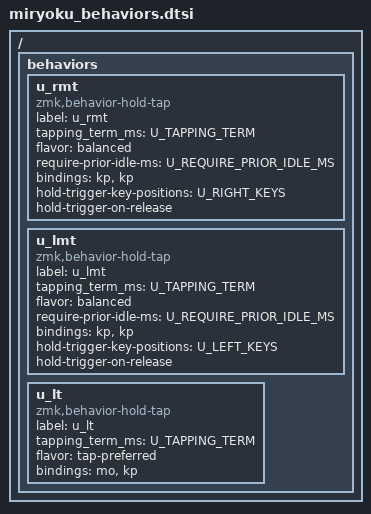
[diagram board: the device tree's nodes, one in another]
// Copyright 2022 Manna Harbour
// https://github.com/manna-harbour/miryoku

/ {
  behaviors {
    u_rmt: u_rmt {
      compatible = "zmk,behavior-hold-tap";
      label = "u_rmt";
      #binding-cells = <2>;
      tapping_term_ms = <U_TAPPING_TERM>;
      flavor = "balanced";
      require-prior-idle-ms = <U_REQUIRE_PRIOR_IDLE_MS>;
      bindings = <&kp>, <&kp>;
      hold-trigger-key-positions = <U_RIGHT_KEYS>;
      hold-trigger-on-release; 
    };

    u_lmt: u_lmt {
      compatible = "zmk,behavior-hold-tap";
      label = "u_lmt";
      #binding-cells = <2>;
      tapping_term_ms = <U_TAPPING_TERM>;
      flavor = "balanced";
      require-prior-idle-ms = <U_REQUIRE_PRIOR_IDLE_MS>;
      bindings = <&kp>, <&kp>;
      hold-trigger-key-positions = <U_LEFT_KEYS>;
      hold-trigger-on-release; 
    };

    u_lt: u_lt {
      compatible = "zmk,behavior-hold-tap";
      label = "u_lt";
      #binding-cells = <2>;
      tapping_term_ms = <U_TAPPING_TERM>;
      flavor = "tap-preferred";
      bindings = <&mo>, <&kp>;
    };
  };
};
